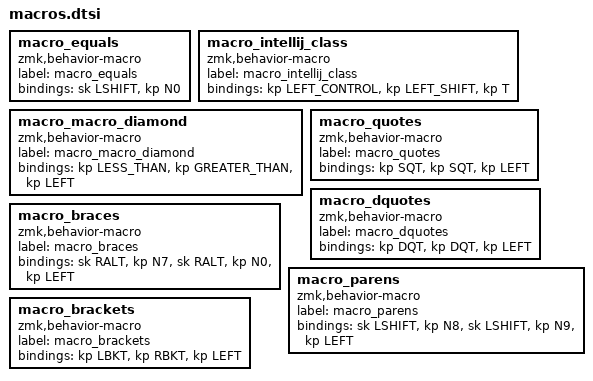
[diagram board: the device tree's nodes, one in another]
macro_equals: macro_equals{
compatible = "zmk,behavior-macro";
label = "macro_equals";
#binding-cells = <0>;
bindings = <&sk LSHIFT>, <&kp N0>;
};
macro_intellij_class: macro_intellij_class{
compatible = "zmk,behavior-macro";
label = "macro_intellij_class";
#binding-cells = <0>;
bindings = <&kp LEFT_CONTROL>, <&kp LEFT_SHIFT>, <&kp T>;
};
macro_macro_diamond: macro_macro_diamond{
compatible = "zmk,behavior-macro";
label = "macro_macro_diamond";
#binding-cells = <0>;
bindings = <&kp LESS_THAN>, <&kp GREATER_THAN>, <&kp LEFT>;
};
macro_quotes: macro_quotes{
compatible = "zmk,behavior-macro";
label = "macro_quotes";
#binding-cells = <0>;
bindings = <&kp SQT>, <&kp SQT>, <&kp LEFT>;
};
macro_dquotes: macro_dquotes{
compatible = "zmk,behavior-macro";
label = "macro_dquotes";
#binding-cells = <0>;
bindings = <&kp DQT>, <&kp DQT>, <&kp LEFT>;
};
macro_braces: macro_braces{
compatible = "zmk,behavior-macro";
label = "macro_braces";
#binding-cells = <0>;
bindings = <&sk RALT>, <&kp N7>, <&sk RALT>, <&kp N0>, <&kp LEFT>;
};
macro_parens: macro_parens{
compatible = "zmk,behavior-macro";
label = "macro_parens";
#binding-cells = <0>;
bindings = <&sk LSHIFT>, <&kp N8>, <&sk LSHIFT>, <&kp N9>, <&kp LEFT>;
};
macro_brackets: macro_brackets{
compatible = "zmk,behavior-macro";
label = "macro_brackets";
#binding-cells = <0>;
bindings = <&kp LBKT>, <&kp RBKT>, <&kp LEFT>;
};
